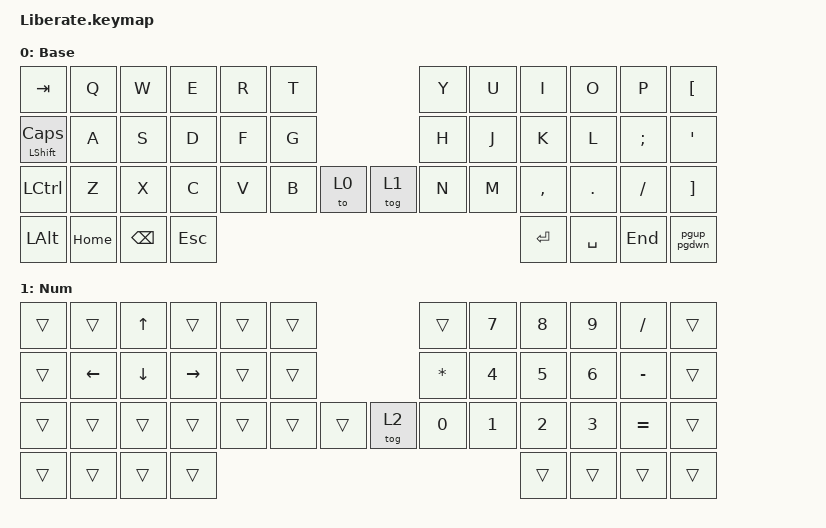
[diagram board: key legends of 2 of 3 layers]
#include <behaviors.dtsi>
#include <dt-bindings/zmk/keys.h>

/ {
    behaviors {
        pgup_pgdwn: pageup_pagedown {
            compatible = "zmk,behavior-mod-morph";
            #binding-cells = <0>;
            bindings = <&kp PG_UP>, <&kp PG_DN>;
            mods = <(MOD_LSFT)>;
            };
        };

    keymap {
        compatible = "zmk,keymap";

        default_layer {
          display-name = "Base";
          bindings = <
              &kp TAB    &kp Q   &kp W   &kp E  &kp R   &kp T                          &kp Y   &kp U   &kp I   &kp O   &kp P      &kp LEFT_BRACKET
              &mt LSHIFT CAPS &kp A &kp S &kp D &kp F   &kp G                          &kp H   &kp J   &kp K   &kp L   &kp SEMI   &kp SQT
              &kp LCTRL  &kp Z  &kp X   &kp C   &kp V   &kp B   &to 0        &tog 1    &kp N   &kp M   &kp COMMA   &kp DOT        &kp SLASH   &kp RIGHT_BRACKET
              &kp LALT   &kp HOME                       &kp BSPC &kp ESC     &kp RET  &kp SPACE                                   &kp END &pgup_pgdwn
            >;
        };
        num_layer {
            display-name = "Num";
            bindings = <
                &trans    &trans    &kp UP    &trans    &trans    &trans                            &trans    &kp N7    &kp N8    &kp N9    &kp SLASH   &trans 
                &trans    &kp LEFT    &kp DOWN    &kp RIGHT    &trans    &trans                     &kp STAR   &kp N4    &kp N5    &kp N6    &kp MINUS   &trans
                &trans    &trans    &trans    &trans    &trans    &trans    &trans        &tog 2    &kp N0    &kp N1    &kp N2    &kp N3    &kp EQUAL    &trans
                &trans    &trans                                  &trans    &trans        &trans    &trans                                  &trans    &trans
            >;
        };
        upgrade_layer {
            display-name = "upgrade";
            bindings = <
                &trans    &trans    &trans    &trans    &trans    &trans    &trans                             &trans    &trans    &trans    &trans    &trans    &trans    &studio_unlock
                &trans    &trans    &trans    &trans    &trans    &trans    &trans                             &trans    &trans    &trans    &trans    &trans    &trans    &trans 
                &trans    &trans    &trans    &trans    &trans    &trans    &trans    &trans         &trans    &trans    &trans    &trans    &trans    &trans    &trans    &trans 
                &trans    &trans                                            &trans    &trans         &trans    &trans                                            &trans    &trans 
            >;
        };
    };

};

